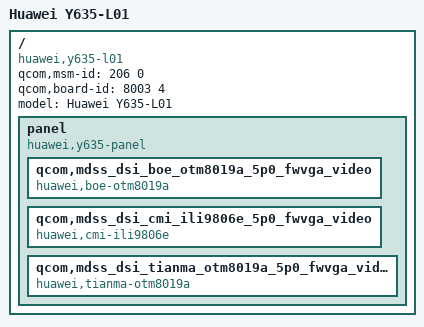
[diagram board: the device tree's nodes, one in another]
// SPDX-License-Identifier: GPL-2.0-only

/dts-v1/;

/*
 * To get a working build for huawei-y635-l01, comment out
 * $(LOCAL_DIR)/msm8916-mtp.dtb in rules.mk in this directory.
 * y635-l01 does not work with msm8916-mtp.dtb enabled; the bootloader
 * gets upset and goes into the phone's fastboot.
 */

#include <skeleton.dtsi>

/ {
	qcom,msm-id = <206 0>;
	qcom,board-id = <8003 4>;

	model = "Huawei Y635-L01";
	compatible = "huawei,y635-l01", "qcom,msm8916", "lk2nd,device";

	panel {
		compatible = "huawei,y635-panel";

		qcom,mdss_dsi_boe_otm8019a_5p0_fwvga_video {
			compatible = "huawei,boe-otm8019a";
		};
		qcom,mdss_dsi_cmi_ili9806e_5p0_fwvga_video {
			compatible = "huawei,cmi-ili9806e";
		};
		qcom,mdss_dsi_tianma_otm8019a_5p0_fwvga_video {
			compatible = "huawei,tianma-otm8019a";
		};
	};
};
